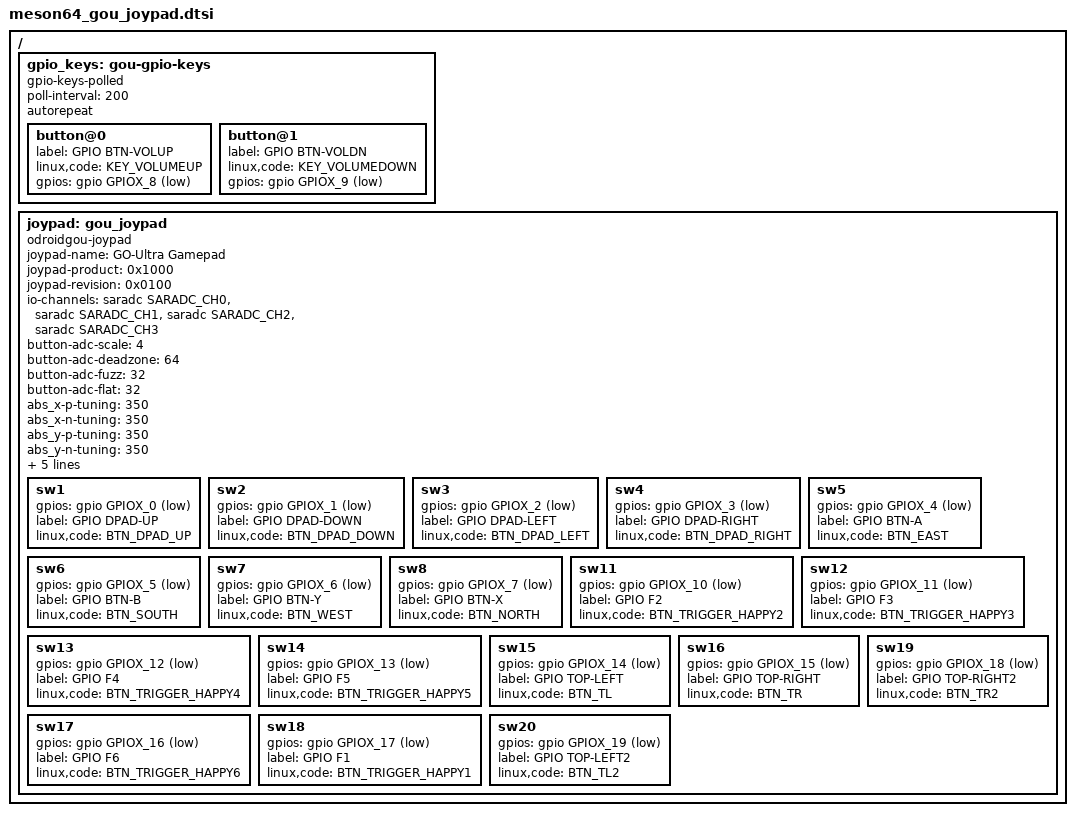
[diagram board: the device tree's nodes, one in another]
/*
 * arch/arm64/boot/dts/amlogic/meson64_gou_joypad.dtsi
 *
 * Copyright (C) 2021 Hardkernel Co,. Ltd. All rights reserved.
 *
 * This program is free software; you can redistribute it and/or modify
 * it under the terms of the GNU General Public License as published by
 * the Free Software Foundation; either version 2 of the License, or
 * (at your option) any later version.
 *
 * This program is distributed in the hope that it will be useful, but WITHOUT
 * ANY WARRANTY; without even the implied warranty of MERCHANTABILITY or
 * FITNESS FOR A PARTICULAR PURPOSE.  See the GNU General Public License for
 * more details.
 *
 */

/{
	gpio_keys: gou-gpio-keys {
		compatible = "gpio-keys-polled";
		poll-interval = <200>;
		autorepeat;

		button@0 {
			label = "GPIO BTN-VOLUP";
			linux,code = <KEY_VOLUMEUP>;
                        gpios = <&gpio GPIOX_8 GPIO_ACTIVE_LOW>;
		};
		button@1 {
			label = "GPIO BTN-VOLDN";
			linux,code = <KEY_VOLUMEDOWN>;
                        gpios = <&gpio GPIOX_9 GPIO_ACTIVE_LOW>;
		};
	};

	joypad: gou_joypad {
                compatible = "odroidgou-joypad";
		status = "okay";

                joypad-name = "GO-Ultra Gamepad";
                joypad-product = <0x1000>;
                joypad-revision = <0x0100>;

                /*
                  - odroidgou-joypad sysfs list -
		   * for poll device interval(ms)
		   /sys/devices/platform/gou_joypad/poll_interval [rw]
		   ex) echo 20 > poll_interval
                   * for button-adc-fuzz
		   /sys/devices/platform/gou_joypad/adc_fuzz [r]
                   * for button-adc-flat
		   /sys/devices/platform/gou_joypad/adc_flat [r]

		   * for report control(1:enable, 0:disable)
		   /sys/devices/platform/gou_joypad/enable [rw]
		   * for adc calibration value setup(current adcs value -> cal value)
		   /sys/devices/platform/gou_joypad/adc_cal [rw]
		   ex) echo 0 > adc_cal
                */

		/* gpio pincontrol setup */
                /* pinctrl-names = "default"; */
                /* pinctrl-0 = <&key_all_pins>; */

		/* Analog mux define */
		io-channels = <&saradc SARADC_CH0>,
			      <&saradc SARADC_CH1>,
			      <&saradc SARADC_CH2>,
			      <&saradc SARADC_CH3>;
		io-channel-names = "key-RY", "key-RX", "key-LY", "key-LX";

		/* adc calculate scale */
		button-adc-scale = <4>;

		/* adc deadzone range  */
		button-adc-deadzone = <64>;

		/*
		  specifies fuzz value that is used to filter noise from
		  the event stream.
		*/
		button-adc-fuzz = <32>;
		button-adc-flat = <32>;

		/*
		  Analog Stick data tuning value(precent)
		  p = positive direction, n = negative direction
		  report value = (real_adc_data * tuning_value) / 100
		*/
		abs_x-p-tuning = <350>;
		abs_x-n-tuning = <350>;

		abs_y-p-tuning = <350>;
		abs_y-n-tuning = <350>;

		abs_rx-p-tuning = <350>;
		abs_rx-n-tuning = <350>;

		abs_ry-p-tuning = <350>;
		abs_ry-n-tuning = <350>;

		/* poll device interval (ms), adc read interval */
		poll-interval = <10>;

		/* gpio button auto repeat set value : default disable */
		/*
			autorepeat;
		*/

		/*    *** ODROID-GOU Switch layoout ***
		|------------------------------------------------|
		| sw15  sw20        sw10   sw9        sw19  sw16 |
		|------------------------------------------------|
		|      sw18                            sw17      |
		|              |-------------------|             |
		|     sw1      |                   |      sw8    |
		|  sw3   sw4   |                   |   sw7   sw5 |
		|     sw2      |    LCD Display    |      sw6    |
		|              |                   |             |
		|    Analog    |                   |    Analog   |
		|              |-------------------|             |
		|  sw11 sw12              |   |       sw13 sw14  |
		|-------------------------|uSD|------------------| */
                /*  joypad driver is poll-device driver.
                    poll-device is does not support wakeup-source.
		*/
                sw1 {
                        gpios = <&gpio GPIOX_0 GPIO_ACTIVE_LOW>;
                        label = "GPIO DPAD-UP";
                        linux,code = <BTN_DPAD_UP>; // 0x220
                };
                sw2 {
                        gpios = <&gpio GPIOX_1 GPIO_ACTIVE_LOW>;
                        label = "GPIO DPAD-DOWN";
                        linux,code = <BTN_DPAD_DOWN>; // 0x221
                };
                sw3 {
                        gpios = <&gpio GPIOX_2 GPIO_ACTIVE_LOW>;
                        label = "GPIO DPAD-LEFT";
                        linux,code = <BTN_DPAD_LEFT>; // 0x222
                };
                sw4 {
                        gpios = <&gpio GPIOX_3 GPIO_ACTIVE_LOW>;
                        label = "GPIO DPAD-RIGHT";
                        linux,code = <BTN_DPAD_RIGHT>; // 0x223
                };
                sw5 {
                        gpios = <&gpio GPIOX_4 GPIO_ACTIVE_LOW>;
                        label = "GPIO BTN-A";
                        linux,code = <BTN_EAST>; // 0x131
                };
                sw6 {
                        gpios = <&gpio GPIOX_5 GPIO_ACTIVE_LOW>;
                        label = "GPIO BTN-B";
                        linux,code = <BTN_SOUTH>; // 0x130
                };
                sw7 {
                        gpios = <&gpio GPIOX_6 GPIO_ACTIVE_LOW>;
                        label = "GPIO BTN-Y";
                        linux,code = <BTN_WEST>; // 0x134
                };
                sw8 {
                        gpios = <&gpio GPIOX_7 GPIO_ACTIVE_LOW>;
                        label = "GPIO BTN-X";
                        linux,code = <BTN_NORTH>; // 0x133
                };
                sw11 {
                        gpios = <&gpio GPIOX_10 GPIO_ACTIVE_LOW>;
                        label = "GPIO F2";
                        linux,code = <BTN_TRIGGER_HAPPY2>; // 0x2c2
                };
                sw12 {
                        gpios = <&gpio GPIOX_11 GPIO_ACTIVE_LOW>;
                        label = "GPIO F3";
                        linux,code = <BTN_TRIGGER_HAPPY3>; // 0x2c3
                };
                sw13 {
                        gpios = <&gpio GPIOX_12 GPIO_ACTIVE_LOW>;
                        label = "GPIO F4";
                        linux,code = <BTN_TRIGGER_HAPPY4>; // 0x2c4
                };
                sw14 {
                        gpios = <&gpio GPIOX_13 GPIO_ACTIVE_LOW>;
                        label = "GPIO F5";
                        linux,code = <BTN_TRIGGER_HAPPY5>; // 0x13c
                };
                sw15 {
                        gpios = <&gpio GPIOX_14 GPIO_ACTIVE_LOW>;
                        label = "GPIO TOP-LEFT";
                        linux,code = <BTN_TL>; // 0x02
                };
                sw16 {
                        gpios = <&gpio GPIOX_15 GPIO_ACTIVE_LOW>;
                        label = "GPIO TOP-RIGHT";
                        linux,code = <BTN_TR>; // 0x05
                };
                sw17 {
                        gpios = <&gpio GPIOX_16 GPIO_ACTIVE_LOW>;
                        label = "GPIO F6";
                        linux,code = <BTN_TRIGGER_HAPPY6>;
                };
                sw18 {
                        gpios = <&gpio GPIOX_17 GPIO_ACTIVE_LOW>;
                        label = "GPIO F1";
                        linux,code = <BTN_TRIGGER_HAPPY1>;
                };
                sw19 {
                        gpios = <&gpio GPIOX_18 GPIO_ACTIVE_LOW>;
                        label = "GPIO TOP-RIGHT2";
                        linux,code = <BTN_TR2>;
                };
                sw20 {
                        gpios = <&gpio GPIOX_19 GPIO_ACTIVE_LOW>;
                        label = "GPIO TOP-LEFT2";
                        linux,code = <BTN_TL2>;
                };
        };
};
